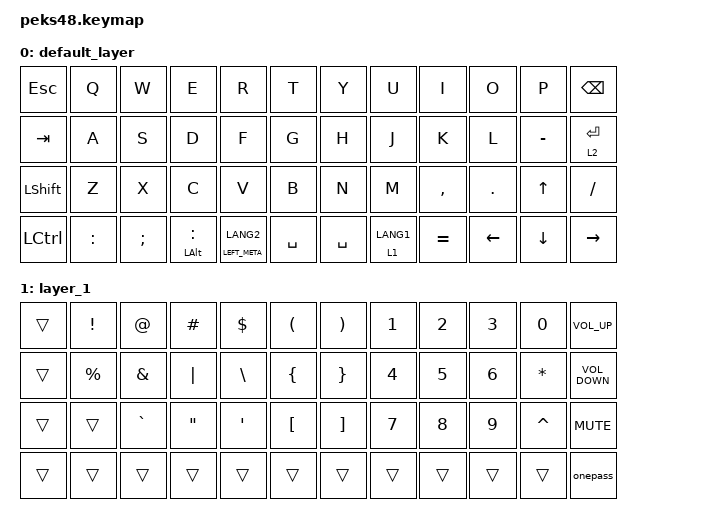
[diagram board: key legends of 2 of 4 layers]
#include <input/processors.dtsi>
#include <dt-bindings/zmk/input_transform.h>
#include <zephyr/dt-bindings/input/input-event-codes.h>
#include <behaviors.dtsi>
#include <dt-bindings/zmk/bt.h>
#include <dt-bindings/zmk/keys.h>

// Conversion definition for using Japanese keyboard with OS settings

#define JP_DQUOTE       AT                // "
#define JP_AMPERSAND    CARET             // &
#define JP_QUOTE        AMPERSAND         // '
#define JP_EQUAL        UNDER             // =
#define JP_CARET        EQUAL             // ^
#define JP_YEN          0x89              // ¥
#define JP_PLUS         COLON             // +
#define JP_TILDE        PLUS              // ~
#define JP_PIPE         LS(0x89)          // |
#define JP_AT           LEFT_BRACKET      // @
#define JP_COLON        SINGLE_QUOTE      // :
#define JP_ASTERISK     DOUBLE_QUOTES     // *
#define JP_BACKQUOTE    LEFT_BRACE        // `
#define JP_UNDERSCORE   LS(0x87)          // _
#define JP_LBRACKET     RIGHT_BRACKET     // [
#define JP_RBRACKET     BACKSLASH         // ]
#define JP_LPAREN       ASTERISK          // (
#define JP_RPAREN       LEFT_PARENTHESIS  // )
#define JP_LBRACE       RIGHT_BRACE       // {
#define JP_RBRACE       PIPE              // }
#define JP_KANA         LANGUAGE_1        // かな
#define JP_EISU         LANGUAGE_2        // 英数
#define JP_HANZEN       GRAVE             // 半角/全角

&mt {
    flavor = "balanced";
    quick-tap-ms = <0>;
};

/ {
    combos { compatible = "zmk,combos"; };

    macros {
        onepass: onepass {
            compatible = "zmk,behavior-macro";
            #binding-cells = <0>;
            bindings = <&kp LS(S) &kp Z &kp R &kp K &kp N9 &kp PRCNT &kp N2 &kp N2 &kp LS(F) &kp H &kp U &kp N1 &kp N8 &kp N3 &kp A &kp LS(S) &kp ENTER>;
            label = "ONEPASS";
        };

        var_dump: var_dump {
            compatible = "zmk,behavior-macro";
            #binding-cells = <0>;
            bindings = <&none &kp V &kp A &kp R &kp UNDER &kp D &kp U &kp M &kp P &kp LPAR &kp RPAR &kp LEFT_ARROW>;
            label = "VAR_DUMP";
        };

        console: console {
            compatible = "zmk,behavior-macro";
            #binding-cells = <0>;
            bindings = <&none &kp C &kp O &kp N &kp S &kp O &kp L &kp E &kp DOT &kp L &kp O &kp G &kp LPAR &kp RPAR &kp LEFT_ARROW>;
            label = "CONSOLE";
        };
    };

    keymap {
        compatible = "zmk,keymap";

        default_layer {
            bindings = <
&kp ESC     &kp Q      &kp W     &kp E               &kp R                &kp T        &kp Y      &kp U        &kp I      &kp O           &kp P           &kp BACKSPACE
&kp TAB     &kp A      &kp S     &kp D               &kp F                &kp G        &kp H      &kp J        &kp K      &kp L           &kp MINUS       &lt 2 ENTER
&kp LSHIFT  &kp Z      &kp X     &kp C               &kp V                &kp B        &kp N      &kp M        &kp COMMA  &kp DOT         &kp UP_ARROW    &kp SLASH
&kp LCTRL   &kp COLON  &kp SEMI  &mt LEFT_ALT COLON  &mt LEFT_META LANG2  &kp SPACE    &kp SPACE  &lt 1 LANG1  &kp EQUAL  &kp LEFT_ARROW  &kp DOWN_ARROW  &kp RIGHT_ARROW
            >;
        };

        layer_1 {
            bindings = <
&trans  &kp EXCL   &kp AT     &kp HASH  &kp DLLR          &kp LPAR    &kp RPAR           &kp NUMBER_1  &kp NUMBER_2  &kp NUMBER_3  &kp NUMBER_0  &kp C_VOL_UP
&trans  &kp PRCNT  &kp AMPS   &kp PIPE  &kp BACKSLASH     &kp LBRC    &kp RBRC           &kp NUMBER_4  &kp NUMBER_5  &kp NUMBER_6  &kp ASTRK     &kp C_VOLUME_DOWN
&trans  &trans     &kp GRAVE  &kp DQT   &kp SINGLE_QUOTE  &kp LBKT    &kp RIGHT_BRACKET  &kp NUMBER_7  &kp NUMBER_8  &kp NUMBER_9  &kp CARET     &kp K_MUTE
&trans  &trans     &trans     &trans    &trans            &trans      &trans             &trans        &trans        &trans        &trans        &onepass
            >;
        };

        layer_2 {
            bindings = <
&trans  &kp F7   &kp LG(LS(NUMBER_4))  &trans    &trans             &trans    &trans  &trans  &trans  &trans                      &trans  &trans
&trans  &kp F12  &kp LS(LG(NUMBER_5))  &trans    &kp LS(LA(LC(F)))  &trans    &trans  &trans  &trans  &trans                      &trans  &trans
&trans  &trans   &trans                &console  &var_dump          &trans    &trans  &trans  &trans  &trans                      &trans  &trans
&trans  &trans   &trans                &trans    &trans             &trans    &trans  &trans  &trans  &kp LS(LA(LC(LEFT_ARROW)))  &trans  &kp LS(LA(LC(RIGHT)))
            >;
        };

        layer_3 {
            bindings = <
&trans  &trans  &trans  &trans  &trans  &trans    &trans  &bt BT_SEL 0  &trans  &trans  &trans  &trans
&trans  &trans  &trans  &trans  &trans  &trans    &trans  &trans        &trans  &trans  &trans  &trans
&trans  &trans  &trans  &trans  &trans  &trans    &trans  &trans        &trans  &trans  &trans  &trans
&trans  &trans  &trans  &trans
            >;
        };
    };
};
